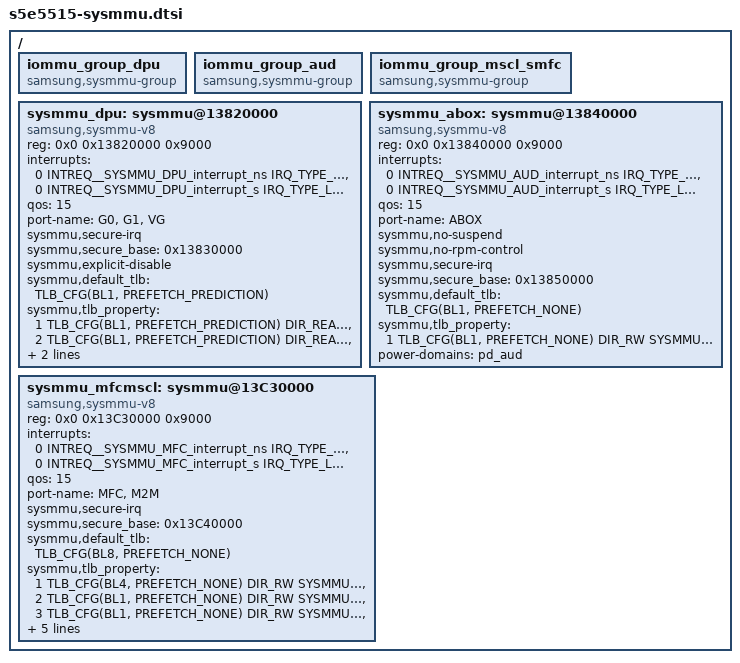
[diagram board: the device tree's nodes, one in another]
/*
 * SAMSUNG S5E5515 SoC device tree source
 *
 * Copyright (c) 2021 Samsung Electronics Co., Ltd.
 *		http://www.samsung.com
 *
 * SAMSUNG S5E5515 SoC device nodes are listed in this file.
 * S5E5515 based board files can include this file and provide
 * values for board specfic bindings.
 *
 * This program is free software; you can redistribute it and/or modify
 * it under the terms of the GNU General Public License version 2 as
 * published by the Free Software Foundation.
 */

#include <dt-bindings/interrupt-controller/s5e5515.h>
#include <dt-bindings/soc/samsung,sysmmu-v8.h>

/ {
	iommu_group_dpu: iommu_group_dpu {
        compatible = "samsung,sysmmu-group";
    };

    iommu_group_aud: iommu_group_aud {
        compatible = "samsung,sysmmu-group";
    };

    iommu_group_mscl_smfc: iommu_group_mscl_smfc {
        compatible = "samsung,sysmmu-group";
    };

	sysmmu_dpu: sysmmu@13820000 {
		compatible = "samsung,sysmmu-v8";
		reg = <0x0 0x13820000 0x9000>;
		interrupts = <0 INTREQ__SYSMMU_DPU_interrupt_ns IRQ_TYPE_LEVEL_HIGH>,
			     <0 INTREQ__SYSMMU_DPU_interrupt_s  IRQ_TYPE_LEVEL_HIGH>;
		qos = <15>;
		port-name = "G0, G1, VG";
		sysmmu,secure-irq;
		sysmmu,secure_base = <0x13830000>;
		#iommu-cells = <0>;
		sysmmu,explicit-disable;
		sysmmu,default_tlb = <TLB_CFG(BL1, PREFETCH_PREDICTION)>;
		sysmmu,tlb_property =
			<1 TLB_CFG(BL1, PREFETCH_PREDICTION) DIR_READ SYSMMU_ID_MASK(0x1, 0xF)>,
			<2 TLB_CFG(BL1, PREFETCH_PREDICTION) DIR_READ SYSMMU_ID_MASK(0x2, 0xF)>,
			<3 TLB_CFG(BL1, PREFETCH_PREDICTION) DIR_READ SYSMMU_ID_MASK(0x3, 0xF)>;
		power-domains = <&pd_disp>;
	};

	sysmmu_abox: sysmmu@13840000 {
		compatible = "samsung,sysmmu-v8";
		reg = <0x0 0x13840000 0x9000>;
		interrupts = <0 INTREQ__SYSMMU_AUD_interrupt_ns IRQ_TYPE_LEVEL_HIGH>,
			     <0 INTREQ__SYSMMU_AUD_interrupt_s  IRQ_TYPE_LEVEL_HIGH>;
		qos = <15>;
		port-name = "ABOX";
		sysmmu,no-suspend;
		sysmmu,no-rpm-control;
		sysmmu,secure-irq;
		sysmmu,secure_base = <0x13850000>;
		#iommu-cells = <0>;
		sysmmu,default_tlb = <TLB_CFG(BL1, PREFETCH_NONE)>;
		sysmmu,tlb_property =
			<1 TLB_CFG(BL1, PREFETCH_NONE) DIR_RW SYSMMU_ID_MASK(0x1, 0x1)>;
		power-domains = <&pd_aud>;
	};

	sysmmu_mfcmscl: sysmmu@13C30000 {
		compatible = "samsung,sysmmu-v8";
		reg = <0x0 0x13C30000 0x9000>;
		interrupts = <0 INTREQ__SYSMMU_MFC_interrupt_ns IRQ_TYPE_LEVEL_HIGH>,
			     <0 INTREQ__SYSMMU_MFC_interrupt_s  IRQ_TYPE_LEVEL_HIGH>;
		qos = <15>;
		port-name = "MFC, M2M";
		sysmmu,secure-irq;
		sysmmu,secure_base = <0x13C40000>;
		#iommu-cells = <0>;
		sysmmu,default_tlb = <TLB_CFG(BL8, PREFETCH_NONE)>;
		sysmmu,tlb_property =
			<1 TLB_CFG(BL4, PREFETCH_NONE) DIR_RW SYSMMU_ID_MASK(0x1, 0x1F)>,
			<2 TLB_CFG(BL1, PREFETCH_NONE) DIR_RW SYSMMU_ID_MASK(0x3, 0x1F)>,
			<3 TLB_CFG(BL1, PREFETCH_NONE) DIR_RW SYSMMU_ID_MASK(0x5, 0x1F)>,
			<4 TLB_CFG(BL1, PREFETCH_NONE) DIR_RW SYSMMU_ID_MASK(0x7, 0x1F)>,
			<5 TLB_CFG(BL4, PREFETCH_NONE) DIR_RW SYSMMU_ID_MASK(0x11, 0x1F)>,
			<6 TLB_CFG(BL1, PREFETCH_NONE) DIR_RW SYSMMU_ID_MASK(0x13, 0x1F)>,
			<7 TLB_CFG(BL1, PREFETCH_NONE) DIR_RW SYSMMU_ID_MASK(0x15, 0x1F)>;
		power-domains = <&pd_mfc>;
	};
};
